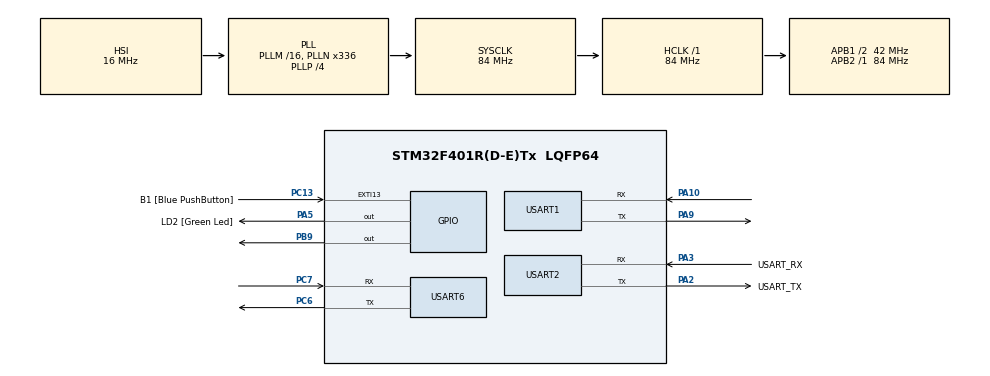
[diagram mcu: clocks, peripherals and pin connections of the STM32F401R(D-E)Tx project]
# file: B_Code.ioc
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Mcu.Family=STM32F4
Mcu.Name=STM32F401R(D-E)Tx
Mcu.Package=LQFP64
NVIC.PriorityGroup=NVIC_PRIORITYGROUP_0
PA10.Mode=Asynchronous
PA10.Signal=USART1_RX
PA13.GPIO_Label=TMS
PA13.Signal=SYS_JTMS-SWDIO
PA14.GPIO_Label=TCK
PA14.Signal=SYS_JTCK-SWCLK
PA2.GPIO_Label=USART_TX
PA2.GPIO_Mode=GPIO_MODE_AF_PP
PA2.GPIO_PuPd=GPIO_NOPULL
PA2.GPIO_Speed=GPIO_SPEED_FREQ_LOW
PA2.Mode=Asynchronous
PA2.Signal=USART2_TX
PA3.GPIO_Label=USART_RX
PA3.GPIO_Mode=GPIO_MODE_AF_PP
PA3.GPIO_PuPd=GPIO_NOPULL
PA3.GPIO_Speed=GPIO_SPEED_FREQ_LOW
PA3.Mode=Asynchronous
PA3.Signal=USART2_RX
PA5.GPIO_Label=LD2 [Green Led]
PA5.GPIO_Mode=GPIO_MODE_OUTPUT_PP
PA5.GPIO_PuPd=GPIO_NOPULL
PA5.GPIO_Speed=GPIO_SPEED_FREQ_LOW
PA5.Signal=GPIO_Output
PA9.Mode=Asynchronous
PA9.Signal=USART1_TX
PB3.GPIO_Label=SWO
PB3.Signal=SYS_JTDO-SWO
PB9.Signal=GPIO_Output
PC13-ANTI_TAMP.GPIO_Label=B1 [Blue PushButton]
PC13-ANTI_TAMP.GPIO_ModeDefaultEXTI=GPIO_MODE_IT_FALLING
PC13-ANTI_TAMP.GPIO_PuPd=GPIO_NOPULL
PC13-ANTI_TAMP.Signal=GPXTI13
PC14-OSC32_IN.Signal=RCC_OSC32_IN
PC15-OSC32_OUT.Signal=RCC_OSC32_OUT
PC6.Mode=Asynchronous
PC6.Signal=USART6_TX
PC7.Mode=Asynchronous
PC7.Signal=USART6_RX
PH0\ -\ OSC_IN.Signal=RCC_OSC_IN
PH1\ -\ OSC_OUT.Signal=RCC_OSC_OUT
ProjectManager.HeapSize=0x200
ProjectManager.StackSize=0x400
ProjectManager.TargetToolchain=SW4STM32
RCC.AHBFreq_Value=84000000
RCC.APB1CLKDivider=RCC_HCLK_DIV2
RCC.APB1Freq_Value=42000000
RCC.APB1TimFreq_Value=84000000
RCC.APB2Freq_Value=84000000
RCC.APB2TimFreq_Value=84000000
RCC.CortexFreq_Value=84000000
RCC.HCLKFreq_Value=84000000
RCC.HSE_VALUE=8000000
RCC.HSI_VALUE=16000000
RCC.LSE_VALUE=32768
RCC.PLLN=336
RCC.PLLP=RCC_PLLP_DIV4
RCC.PLLQ=7
RCC.SYSCLKFreq_VALUE=84000000
RCC.SYSCLKSource=RCC_SYSCLKSOURCE_PLLCLK
RCC.VCOOutputFreq_Value=336000000
USART1.VirtualMode=VM_ASYNC
USART2.VirtualMode=VM_ASYNC
USART6.VirtualMode=VM_ASYNC
board=NUCLEO-F401RE

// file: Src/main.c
/**
  ******************************************************************************
  * File Name          : main.c
  * Description        : Main program body
  ******************************************************************************
  ** This notice applies to any and all portions of this file
  * that are not between comment pairs USER CODE BEGIN and
  * USER CODE END. Other portions of this file, whether
  * inserted by the user or by software development tools
  * are owned by their respective copyright owners.
  *
  * COPYRIGHT(c) 2017 STMicroelectronics
  *
  * Redistribution and use in source and binary forms, with or without modification,
  * are permitted provided that the following conditions are met:
  *   1. Redistributions of source code must retain the above copyright notice,
  *      this list of conditions and the following disclaimer.
  *   2. Redistributions in binary form must reproduce the above copyright notice,
  *      this list of conditions and the following disclaimer in the documentation
  *      and/or other materials provided with the distribution.
  *   3. Neither the name of STMicroelectronics nor the names of its contributors
  *      may be used to endorse or promote products derived from this software
  *      without specific prior written permission.
  *
  * THIS SOFTWARE IS PROVIDED BY THE COPYRIGHT HOLDERS AND CONTRIBUTORS "AS IS"
  * AND ANY EXPRESS OR IMPLIED WARRANTIES, INCLUDING, BUT NOT LIMITED TO, THE
  * IMPLIED WARRANTIES OF MERCHANTABILITY AND FITNESS FOR A PARTICULAR PURPOSE ARE
  * DISCLAIMED. IN NO EVENT SHALL THE COPYRIGHT HOLDER OR CONTRIBUTORS BE LIABLE
  * FOR ANY DIRECT, INDIRECT, INCIDENTAL, SPECIAL, EXEMPLARY, OR CONSEQUENTIAL
  * DAMAGES (INCLUDING, BUT NOT LIMITED TO, PROCUREMENT OF SUBSTITUTE GOODS OR
  * SERVICES; LOSS OF USE, DATA, OR PROFITS; OR BUSINESS INTERRUPTION) HOWEVER
  * CAUSED AND ON ANY THEORY OF LIABILITY, WHETHER IN CONTRACT, STRICT LIABILITY,
  * OR TORT (INCLUDING NEGLIGENCE OR OTHERWISE) ARISING IN ANY WAY OUT OF THE USE
  * OF THIS SOFTWARE, EVEN IF ADVISED OF THE POSSIBILITY OF SUCH DAMAGE.
  *
  ******************************************************************************
  */
#include "main.h"
#include "stm32f4xx_hal.h"
#include <string.h>
#include <stdlib.h>
#include <stdio.h>

UART_HandleTypeDef huart1;
UART_HandleTypeDef huart2;
UART_HandleTypeDef huart6;

/* USER CODE BEGIN PV */
/* Private variables ---------------------------------------------------------*/
//definition for boolean variables used in conditional statements
#define TRUE 1
#define FALSE 0

//Each board must have a different ID, and will have certain settings based on that ID.
//The settings are declared in a switch case in the STM_BOARD_Init
#define STM_ID 2

//Standard definitions for system
#define BUFFER_SIZE 16
#define WAIT_TIME 50
#define RESET_TIME 500
//Time used in Serial communication reading and sending
#define timeOut 0x0FFF

//Structure declaring board settings, which may vary depending on the board. Determined using STM_ID
struct board {
	char data[BUFFER_SIZE];
	char letter;
}STM_A, STM_B, STM_C;
/* USER CODE END PV */

void SystemClock_Config(void);
static void MX_GPIO_Init(void);
static void MX_USART1_UART_Init(void);
static void MX_USART2_UART_Init(void);
static void MX_USART6_UART_Init(void);

/* USER CODE BEGIN PFP */
/* Private function prototypes -----------------------------------------------*/
void STM_BOARD_Init(void);
void printStringToConsole(char message[]);
void compareData();
void clearArray(uint8_t *buffer);
/* USER CODE END PFP */

int main(void)
{

  /* USER CODE BEGIN 1 */
  STM_BOARD_Init();
  /* USER CODE END 1 */

  /* MCU Configuration----------------------------------------------------------*/

  /* Reset of all peripherals, Initializes the Flash interface and the Systick. */
  HAL_Init();

  /* Configure the system clock */
  SystemClock_Config();

  /* Initialize all configured peripherals */
  MX_GPIO_Init();
  MX_USART1_UART_Init();
  MX_USART2_UART_Init();
  MX_USART6_UART_Init();

  /* USER CODE BEGIN 2 */

  	/* Operational Loop --------------------------------------- */
  	// Initialize B's memory
  char* testString = "Hello!\n";
  int i;
  for(i=0; i<strlen(testString); i++){
  	STM_B.data[i] = testString[i];
  }
  printStringToConsole("B initialized.\n");
  /* USER CODE END 2 */

  /* Infinite loop */
  while (1)
  {
	  if (HAL_GPIO_ReadPin(GPIOC, GPIO_PIN_9))
		  compareData();
	 // printStringToConsole("B Finished Comparing\n");
  }

}

/** System Clock Configuration
*/
void SystemClock_Config(void)
{

  RCC_OscInitTypeDef RCC_OscInitStruct;
  RCC_ClkInitTypeDef RCC_ClkInitStruct;

    /**Configure the main internal regulator output voltage
    */
  __HAL_RCC_PWR_CLK_ENABLE();

  __HAL_PWR_VOLTAGESCALING_CONFIG(PWR_REGULATOR_VOLTAGE_SCALE2);

    /**Initializes the CPU, AHB and APB busses clocks
    */
  RCC_OscInitStruct.OscillatorType = RCC_OSCILLATORTYPE_HSI;
  RCC_OscInitStruct.HSIState = RCC_HSI_ON;
  RCC_OscInitStruct.HSICalibrationValue = 16;
  RCC_OscInitStruct.PLL.PLLState = RCC_PLL_ON;
  RCC_OscInitStruct.PLL.PLLSource = RCC_PLLSOURCE_HSI;
  RCC_OscInitStruct.PLL.PLLM = 16;
  RCC_OscInitStruct.PLL.PLLN = 336;
  RCC_OscInitStruct.PLL.PLLP = RCC_PLLP_DIV4;
  RCC_OscInitStruct.PLL.PLLQ = 7;
  if (HAL_RCC_OscConfig(&RCC_OscInitStruct) != HAL_OK)
  {
    _Error_Handler(__FILE__, __LINE__);
  }

    /**Initializes the CPU, AHB and APB busses clocks
    */
  RCC_ClkInitStruct.ClockType = RCC_CLOCKTYPE_HCLK|RCC_CLOCKTYPE_SYSCLK
                              |RCC_CLOCKTYPE_PCLK1|RCC_CLOCKTYPE_PCLK2;
  RCC_ClkInitStruct.SYSCLKSource = RCC_SYSCLKSOURCE_PLLCLK;
  RCC_ClkInitStruct.AHBCLKDivider = RCC_SYSCLK_DIV1;
  RCC_ClkInitStruct.APB1CLKDivider = RCC_HCLK_DIV2;
  RCC_ClkInitStruct.APB2CLKDivider = RCC_HCLK_DIV1;

  if (HAL_RCC_ClockConfig(&RCC_ClkInitStruct, FLASH_LATENCY_2) != HAL_OK)
  {
    _Error_Handler(__FILE__, __LINE__);
  }

    /**Configure the Systick interrupt time
    */
  HAL_SYSTICK_Config(HAL_RCC_GetHCLKFreq()/1000);

    /**Configure the Systick
    */
  HAL_SYSTICK_CLKSourceConfig(SYSTICK_CLKSOURCE_HCLK);

  /* SysTick_IRQn interrupt configuration */
  HAL_NVIC_SetPriority(SysTick_IRQn, 0, 0);
}

/* USART1 init function */
static void MX_USART1_UART_Init(void)
{

  huart1.Instance = USART1;
  huart1.Init.BaudRate = 115200;
  huart1.Init.WordLength = UART_WORDLENGTH_8B;
  huart1.Init.StopBits = UART_STOPBITS_1;
  huart1.Init.Parity = UART_PARITY_NONE;
  huart1.Init.Mode = UART_MODE_TX_RX;
  huart1.Init.HwFlowCtl = UART_HWCONTROL_NONE;
  huart1.Init.OverSampling = UART_OVERSAMPLING_16;
  if (HAL_UART_Init(&huart1) != HAL_OK)
  {
    _Error_Handler(__FILE__, __LINE__);
  }

}

/* USART2 init function */
static void MX_USART2_UART_Init(void)
{

  huart2.Instance = USART2;
  huart2.Init.BaudRate = 115200;
  huart2.Init.WordLength = UART_WORDLENGTH_8B;
  huart2.Init.StopBits = UART_STOPBITS_1;
  huart2.Init.Parity = UART_PARITY_NONE;
  huart2.Init.Mode = UART_MODE_TX_RX;
  huart2.Init.HwFlowCtl = UART_HWCONTROL_NONE;
  huart2.Init.OverSampling = UART_OVERSAMPLING_16;
  if (HAL_UART_Init(&huart2) != HAL_OK)
  {
    _Error_Handler(__FILE__, __LINE__);
  }

}

/* USART6 init function */
static void MX_USART6_UART_Init(void)
{

  huart6.Instance = USART6;
  huart6.Init.BaudRate = 115200;
  huart6.Init.WordLength = UART_WORDLENGTH_8B;
  huart6.Init.StopBits = UART_STOPBITS_1;
  huart6.Init.Parity = UART_PARITY_NONE;
  huart6.Init.Mode = UART_MODE_TX_RX;
  huart6.Init.HwFlowCtl = UART_HWCONTROL_NONE;
  huart6.Init.OverSampling = UART_OVERSAMPLING_16;
  if (HAL_UART_Init(&huart6) != HAL_OK)
  {
    _Error_Handler(__FILE__, __LINE__);
  }

}

/** Configure pins as
        * Analog
        * Input
        * Output
        * EVENT_OUT
        * EXTI
*/
static void MX_GPIO_Init(void)
{

  GPIO_InitTypeDef GPIO_InitStruct;

  /* GPIO Ports Clock Enable */
  __HAL_RCC_GPIOC_CLK_ENABLE();
  __HAL_RCC_GPIOH_CLK_ENABLE();
  __HAL_RCC_GPIOA_CLK_ENABLE();
  __HAL_RCC_GPIOB_CLK_ENABLE();

  /*Configure GPIO pin Output Level */
  HAL_GPIO_WritePin(LD2_GPIO_Port, LD2_Pin, GPIO_PIN_RESET);

  /*Configure GPIO pin Output Level */
  HAL_GPIO_WritePin(GPIOB, GPIO_PIN_9, GPIO_PIN_RESET);

  /*Configure GPIO pin : B1_Pin */
  GPIO_InitStruct.Pin = B1_Pin;
  GPIO_InitStruct.Mode = GPIO_MODE_IT_FALLING;
  GPIO_InitStruct.Pull = GPIO_NOPULL;
  HAL_GPIO_Init(B1_GPIO_Port, &GPIO_InitStruct);

  /*Configure GPIO pin : LD2_Pin */
  GPIO_InitStruct.Pin = LD2_Pin;
  GPIO_InitStruct.Mode = GPIO_MODE_OUTPUT_PP;
  GPIO_InitStruct.Pull = GPIO_NOPULL;
  GPIO_InitStruct.Speed = GPIO_SPEED_FREQ_LOW;
  HAL_GPIO_Init(LD2_GPIO_Port, &GPIO_InitStruct);

  /*Configure GPIO pin : PB9 */
  GPIO_InitStruct.Pin = GPIO_PIN_9;
  GPIO_InitStruct.Mode = GPIO_MODE_OUTPUT_PP;
  GPIO_InitStruct.Pull = GPIO_NOPULL;
  GPIO_InitStruct.Speed = GPIO_SPEED_FREQ_LOW;
  HAL_GPIO_Init(GPIOB, &GPIO_InitStruct);

  /*Configure GPIO pin : PC9 */
  GPIO_InitStruct.Pin = GPIO_PIN_9;
  GPIO_InitStruct.Mode = GPIO_MODE_IT_RISING;
  GPIO_InitStruct.Pull = GPIO_NOPULL;
  HAL_GPIO_Init(GPIOC, &GPIO_InitStruct);
}

/* USER CODE BEGIN 4 */
void STM_BOARD_Init(void){
	//Declare letter to identify boards for output messages.
	STM_A.letter = 'A';
	STM_B.letter = 'B';
	STM_C.letter = 'C';
	//Clear data buffers.
	clearArray(STM_A.data);
	clearArray(STM_B.data);
	clearArray(STM_C.data);
}

void printStringToConsole(char message[]) {
	if (HAL_UART_Transmit(&huart2, (uint8_t*)message, strlen(message), timeOut) == HAL_OK) {
	}
}

void compareData(){
	int reqBytes = 2;
	int baseIndex, numBytes;

	char baseIndex_s[8];
	char numBytes_s[8];

	uint8_t tempBuffer[BUFFER_SIZE];
	clearArray(tempBuffer);

	// Wait until A sends the request string --------------------------
	int received = 0;
	while(received == 0){
		if(HAL_UART_Receive(&huart1, tempBuffer, reqBytes, timeOut) == HAL_OK)
			received = 1;
	}

	printStringToConsole("B: Received data from A\n");
	printStringToConsole(tempBuffer);
	// Parse data request string ------------------------
	baseIndex_s[0] = tempBuffer[0];
	baseIndex_s[1] = '\0';

	// Store numBytes
	numBytes_s[0] = tempBuffer[1];
	numBytes_s[1] = '\0';

	// Convert from bytes to int
	baseIndex = atoi(baseIndex_s);
	numBytes = atoi(numBytes_s);

	// Generate data array ------------------------
	uint8_t reqData[numBytes];
	clearArray(reqData);

	// Transfer data from internal storage to msg buffer
	for(int count = 0; count < numBytes; count++){
		reqData[count] = STM_B.data[baseIndex+count];
	}

	HAL_Delay(500);
	// Send data to A ----------------------------
	printStringToConsole("\nB:Beginning transmission\n");

	if (HAL_UART_Transmit(&huart1, (uint8_t*)reqData, strlen(reqData), timeOut) == HAL_OK)
		printStringToConsole("B: Sent data to A!\n");
	// Get reset or not --------------------------
}

//clearArray(): This function writes null bytes to the buffer array passed to it
//Input: buffer that needs to be cleared
//Output: None
void clearArray(uint8_t *buffer){
	for (int i = 0; i < BUFFER_SIZE; i++) {
		buffer[i] = '\0';
	}
}
/* USER CODE END 4 */

void _Error_Handler(char * file, int line)
{
  while(1)
  {
  }
}

/************************ (C) COPYRIGHT STMicroelectronics *****END OF FILE****/
